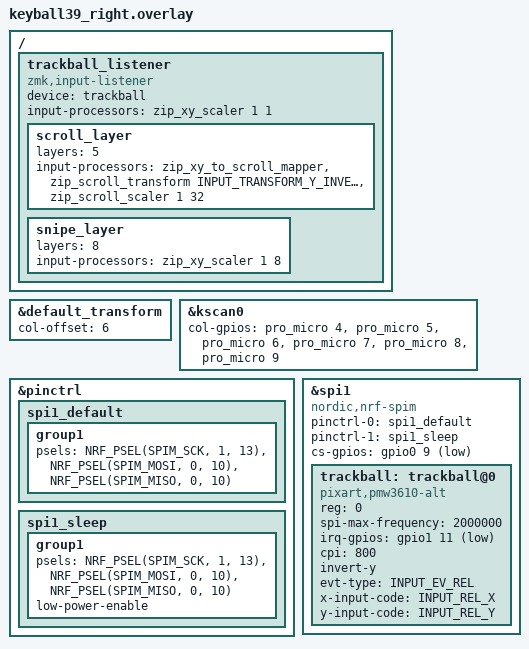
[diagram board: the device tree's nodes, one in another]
/*
 * Copyright (c) 2020 ZMK Contributors
 *
 * SPDX-License-Identifier: MIT
 */

#include "keyball39.dtsi"
#include <zephyr/dt-bindings/input/input-event-codes.h>
#include <dt-bindings/zmk/input_transform.h>
#include <input/processors.dtsi>

&default_transform {
    col-offset = <6>;
};

&kscan0 {
    col-gpios
        = <&pro_micro 4 GPIO_ACTIVE_HIGH>
        , <&pro_micro 5 GPIO_ACTIVE_HIGH>
        , <&pro_micro 6 GPIO_ACTIVE_HIGH>
        , <&pro_micro 7 GPIO_ACTIVE_HIGH>
        , <&pro_micro 8 GPIO_ACTIVE_HIGH>
        , <&pro_micro 9 GPIO_ACTIVE_HIGH>;
};

/*
 * Keyball39 PMW3610 wiring is 3-wire SPI/SDIO:
 * SCK=P1.13, SDIO=P0.10 (shared MOSI/MISO), CS=P0.09, MOTION=P1.11.
 */
&pinctrl {
    spi1_default: spi1_default {
        group1 {
            psels = <NRF_PSEL(SPIM_SCK, 1, 13)>,
                    <NRF_PSEL(SPIM_MOSI, 0, 10)>,
                    <NRF_PSEL(SPIM_MISO, 0, 10)>;
        };
    };

    spi1_sleep: spi1_sleep {
        group1 {
            psels = <NRF_PSEL(SPIM_SCK, 1, 13)>,
                    <NRF_PSEL(SPIM_MOSI, 0, 10)>,
                    <NRF_PSEL(SPIM_MISO, 0, 10)>;
            low-power-enable;
        };
    };
};

&spi1 {
    status = "okay";
    compatible = "nordic,nrf-spim";
    pinctrl-0 = <&spi1_default>;
    pinctrl-1 = <&spi1_sleep>;
    pinctrl-names = "default", "sleep";
    cs-gpios = <&gpio0 9 GPIO_ACTIVE_LOW>;

    trackball: trackball@0 {
        status = "okay";
        compatible = "pixart,pmw3610-alt";
        reg = <0>;
        spi-max-frequency = <2000000>;
        irq-gpios = <&gpio1 11 (GPIO_ACTIVE_LOW | GPIO_PULL_UP)>;
        cpi = <800>;
        invert-y;
        evt-type = <INPUT_EV_REL>;
        x-input-code = <INPUT_REL_X>;
        y-input-code = <INPUT_REL_Y>;
    };
};

/ {
    trackball_listener: trackball_listener {
        compatible = "zmk,input-listener";
        device = <&trackball>;

        /* 800 CPI, 1:1 cursor movement. Mouse layer 4 is activated manually. */
        input-processors = <&zip_xy_scaler 1 1>;

        scroll_layer {
            layers = <5>;
            input-processors = <&zip_xy_to_scroll_mapper>,
                               <&zip_scroll_transform INPUT_TRANSFORM_Y_INVERT>,
                               <&zip_scroll_scaler 1 32>;
        };

        /* Snipe layer 8 uses one eighth of the normal cursor speed. */
        snipe_layer {
            layers = <8>;
            input-processors = <&zip_xy_scaler 1 8>;
        };
    };
};
